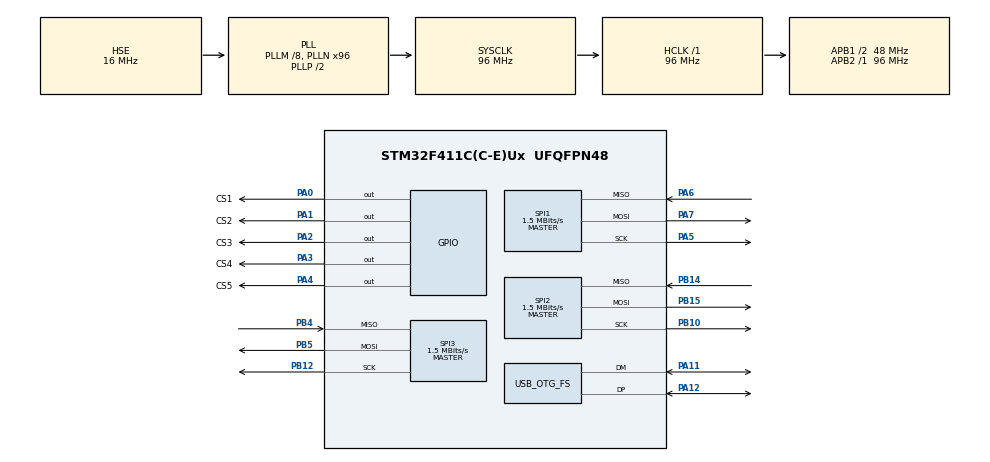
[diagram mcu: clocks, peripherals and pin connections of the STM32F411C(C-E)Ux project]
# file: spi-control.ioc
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Mcu.Family=STM32F4
Mcu.Name=STM32F411C(C-E)Ux
Mcu.Package=UFQFPN48
NVIC.OTG_FS_IRQn=true\:1\:0\:true\:false\:true\:false\:true\:true
NVIC.PriorityGroup=NVIC_PRIORITYGROUP_4
NVIC.TIM1_UP_TIM10_IRQn=true\:0\:0\:true\:false\:true\:true\:true\:true
PA0-WKUP.GPIO_Label=CS1
PA0-WKUP.PinState=GPIO_PIN_SET
PA0-WKUP.Signal=GPIO_Output
PA1.GPIO_Label=CS2
PA1.PinState=GPIO_PIN_SET
PA1.Signal=GPIO_Output
PA11.Mode=Device_Only
PA11.Signal=USB_OTG_FS_DM
PA12.Mode=Device_Only
PA12.Signal=USB_OTG_FS_DP
PA13.Mode=Serial_Wire
PA13.Signal=SYS_JTMS-SWDIO
PA14.Mode=Serial_Wire
PA14.Signal=SYS_JTCK-SWCLK
PA2.GPIO_Label=CS3
PA2.PinState=GPIO_PIN_SET
PA2.Signal=GPIO_Output
PA3.GPIO_Label=CS4
PA3.PinState=GPIO_PIN_SET
PA3.Signal=GPIO_Output
PA4.GPIO_Label=CS5
PA4.PinState=GPIO_PIN_SET
PA4.Signal=GPIO_Output
PA5.Mode=Full_Duplex_Master
PA5.Signal=SPI1_SCK
PA6.Mode=Full_Duplex_Master
PA6.Signal=SPI1_MISO
PA7.Mode=Full_Duplex_Master
PA7.Signal=SPI1_MOSI
PB10.Mode=Full_Duplex_Master
PB10.Signal=SPI2_SCK
PB12.Mode=Full_Duplex_Master
PB12.Signal=SPI3_SCK
PB14.Mode=Full_Duplex_Master
PB14.Signal=SPI2_MISO
PB15.Mode=Full_Duplex_Master
PB15.Signal=SPI2_MOSI
PB4.Mode=Full_Duplex_Master
PB4.Signal=SPI3_MISO
PB5.Mode=Full_Duplex_Master
PB5.Signal=SPI3_MOSI
PH0\ -\ OSC_IN.Mode=HSE-External-Oscillator
PH0\ -\ OSC_IN.Signal=RCC_OSC_IN
PH1\ -\ OSC_OUT.Mode=HSE-External-Oscillator
PH1\ -\ OSC_OUT.Signal=RCC_OSC_OUT
ProjectManager.HeapSize=0x200
ProjectManager.StackSize=0x400
ProjectManager.TargetToolchain=STM32CubeIDE
RCC.48MHZClocksFreq_Value=48000000
RCC.AHBFreq_Value=96000000
RCC.APB1CLKDivider=RCC_HCLK_DIV2
RCC.APB1Freq_Value=48000000
RCC.APB1TimFreq_Value=96000000
RCC.APB2Freq_Value=96000000
RCC.APB2TimFreq_Value=96000000
RCC.CortexFreq_Value=96000000
RCC.HCLKFreq_Value=96000000
RCC.HSE_VALUE=16000000
RCC.HSI_VALUE=16000000
RCC.LSE_VALUE=32768
RCC.PLLM=8
RCC.PLLN=96
RCC.SYSCLKFreq_VALUE=96000000
RCC.SYSCLKSource=RCC_SYSCLKSOURCE_PLLCLK
RCC.VCOOutputFreq_Value=192000000
SPI1.BaudRatePrescaler=SPI_BAUDRATEPRESCALER_64
SPI1.CalculateBaudRate=1.5 MBits/s
SPI1.DataSize=SPI_DATASIZE_8BIT
SPI1.Direction=SPI_DIRECTION_2LINES
SPI1.Mode=SPI_MODE_MASTER
SPI1.VirtualType=VM_MASTER
SPI2.BaudRatePrescaler=SPI_BAUDRATEPRESCALER_32
SPI2.CalculateBaudRate=1.5 MBits/s
SPI2.Direction=SPI_DIRECTION_2LINES
SPI2.Mode=SPI_MODE_MASTER
SPI2.VirtualType=VM_MASTER
SPI3.BaudRatePrescaler=SPI_BAUDRATEPRESCALER_32
SPI3.CalculateBaudRate=1.5 MBits/s
SPI3.Direction=SPI_DIRECTION_2LINES
SPI3.Mode=SPI_MODE_MASTER
SPI3.VirtualType=VM_MASTER
TIM1.Period=5000-1
TIM1.Prescaler=96-1
USB_DEVICE.CLASS_NAME_FS=CDC
USB_DEVICE.PRODUCT_STRING_CDC_FS=soft-hand
USB_DEVICE.VirtualMode=Cdc
USB_DEVICE.VirtualModeFS=Cdc_FS
USB_OTG_FS.VirtualMode=Device_Only
VP_TIM1_VS_ClockSourceINT.Mode=Internal
VP_USB_DEVICE_VS_USB_DEVICE_CDC_FS.Mode=CDC_FS
board=custom

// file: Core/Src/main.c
/* USER CODE BEGIN Header */
/**
  ******************************************************************************
  * @file           : main.c
  * @brief          : Main program body
  ******************************************************************************
  * @attention
  *
  * Copyright (c) 2024 STMicroelectronics.
  * All rights reserved.
  *
  * This software is licensed under terms that can be found in the LICENSE file
  * in the root directory of this software component.
  * If no LICENSE file comes with this software, it is provided AS-IS.
  *
  ******************************************************************************
  */
/* USER CODE END Header */
#include "main.h"
#include "usb_device.h"

/* USER CODE BEGIN Includes */
#include "app.h"
/* USER CODE END Includes */

SPI_HandleTypeDef hspi1;
SPI_HandleTypeDef hspi2;
SPI_HandleTypeDef hspi3;

TIM_HandleTypeDef htim1;

void SystemClock_Config(void);
static void MX_GPIO_Init(void);
static void MX_SPI1_Init(void);
static void MX_SPI2_Init(void);
static void MX_SPI3_Init(void);
static void MX_TIM1_Init(void);

int main(void)
{

  /* MCU Configuration--------------------------------------------------------*/

  /* Reset of all peripherals, Initializes the Flash interface and the Systick. */
  HAL_Init();

  /* Configure the system clock */
  SystemClock_Config();

  /* Initialize all configured peripherals */
  MX_GPIO_Init();
  MX_SPI1_Init();
  MX_SPI2_Init();
  MX_SPI3_Init();
  MX_USB_DEVICE_Init();
  MX_TIM1_Init();

  /* Infinite loop */
  /* USER CODE BEGIN WHILE */
  HAL_Delay(10);
  App_Init();
  while (1)
  {
	  App_Update();
    /* USER CODE END WHILE */

  }
}

void SystemClock_Config(void)
{
  RCC_OscInitTypeDef RCC_OscInitStruct = {0};
  RCC_ClkInitTypeDef RCC_ClkInitStruct = {0};

  /** Configure the main internal regulator output voltage
  */
  __HAL_RCC_PWR_CLK_ENABLE();
  __HAL_PWR_VOLTAGESCALING_CONFIG(PWR_REGULATOR_VOLTAGE_SCALE1);

  /** Initializes the RCC Oscillators according to the specified parameters
  * in the RCC_OscInitTypeDef structure.
  */
  RCC_OscInitStruct.OscillatorType = RCC_OSCILLATORTYPE_HSE;
  RCC_OscInitStruct.HSEState = RCC_HSE_ON;
  RCC_OscInitStruct.PLL.PLLState = RCC_PLL_ON;
  RCC_OscInitStruct.PLL.PLLSource = RCC_PLLSOURCE_HSE;
  RCC_OscInitStruct.PLL.PLLM = 8;
  RCC_OscInitStruct.PLL.PLLN = 96;
  RCC_OscInitStruct.PLL.PLLP = RCC_PLLP_DIV2;
  RCC_OscInitStruct.PLL.PLLQ = 4;
  if (HAL_RCC_OscConfig(&RCC_OscInitStruct) != HAL_OK)
  {
    Error_Handler();
  }

  /** Initializes the CPU, AHB and APB buses clocks
  */
  RCC_ClkInitStruct.ClockType = RCC_CLOCKTYPE_HCLK|RCC_CLOCKTYPE_SYSCLK
                              |RCC_CLOCKTYPE_PCLK1|RCC_CLOCKTYPE_PCLK2;
  RCC_ClkInitStruct.SYSCLKSource = RCC_SYSCLKSOURCE_PLLCLK;
  RCC_ClkInitStruct.AHBCLKDivider = RCC_SYSCLK_DIV1;
  RCC_ClkInitStruct.APB1CLKDivider = RCC_HCLK_DIV2;
  RCC_ClkInitStruct.APB2CLKDivider = RCC_HCLK_DIV1;

  if (HAL_RCC_ClockConfig(&RCC_ClkInitStruct, FLASH_LATENCY_3) != HAL_OK)
  {
    Error_Handler();
  }
}

static void MX_SPI1_Init(void)
{

  /* SPI1 parameter configuration*/
  hspi1.Instance = SPI1;
  hspi1.Init.Mode = SPI_MODE_MASTER;
  hspi1.Init.Direction = SPI_DIRECTION_2LINES;
  hspi1.Init.DataSize = SPI_DATASIZE_8BIT;
  hspi1.Init.CLKPolarity = SPI_POLARITY_LOW;
  hspi1.Init.CLKPhase = SPI_PHASE_1EDGE;
  hspi1.Init.NSS = SPI_NSS_SOFT;
  hspi1.Init.BaudRatePrescaler = SPI_BAUDRATEPRESCALER_64;
  hspi1.Init.FirstBit = SPI_FIRSTBIT_MSB;
  hspi1.Init.TIMode = SPI_TIMODE_DISABLE;
  hspi1.Init.CRCCalculation = SPI_CRCCALCULATION_DISABLE;
  hspi1.Init.CRCPolynomial = 10;
  if (HAL_SPI_Init(&hspi1) != HAL_OK)
  {
    Error_Handler();
  }

}

static void MX_SPI2_Init(void)
{

  /* SPI2 parameter configuration*/
  hspi2.Instance = SPI2;
  hspi2.Init.Mode = SPI_MODE_MASTER;
  hspi2.Init.Direction = SPI_DIRECTION_2LINES;
  hspi2.Init.DataSize = SPI_DATASIZE_8BIT;
  hspi2.Init.CLKPolarity = SPI_POLARITY_LOW;
  hspi2.Init.CLKPhase = SPI_PHASE_1EDGE;
  hspi2.Init.NSS = SPI_NSS_SOFT;
  hspi2.Init.BaudRatePrescaler = SPI_BAUDRATEPRESCALER_32;
  hspi2.Init.FirstBit = SPI_FIRSTBIT_MSB;
  hspi2.Init.TIMode = SPI_TIMODE_DISABLE;
  hspi2.Init.CRCCalculation = SPI_CRCCALCULATION_DISABLE;
  hspi2.Init.CRCPolynomial = 10;
  if (HAL_SPI_Init(&hspi2) != HAL_OK)
  {
    Error_Handler();
  }

}

static void MX_SPI3_Init(void)
{

  /* SPI3 parameter configuration*/
  hspi3.Instance = SPI3;
  hspi3.Init.Mode = SPI_MODE_MASTER;
  hspi3.Init.Direction = SPI_DIRECTION_2LINES;
  hspi3.Init.DataSize = SPI_DATASIZE_8BIT;
  hspi3.Init.CLKPolarity = SPI_POLARITY_LOW;
  hspi3.Init.CLKPhase = SPI_PHASE_1EDGE;
  hspi3.Init.NSS = SPI_NSS_SOFT;
  hspi3.Init.BaudRatePrescaler = SPI_BAUDRATEPRESCALER_32;
  hspi3.Init.FirstBit = SPI_FIRSTBIT_MSB;
  hspi3.Init.TIMode = SPI_TIMODE_DISABLE;
  hspi3.Init.CRCCalculation = SPI_CRCCALCULATION_DISABLE;
  hspi3.Init.CRCPolynomial = 10;
  if (HAL_SPI_Init(&hspi3) != HAL_OK)
  {
    Error_Handler();
  }

}

static void MX_TIM1_Init(void)
{

  TIM_ClockConfigTypeDef sClockSourceConfig = {0};
  TIM_MasterConfigTypeDef sMasterConfig = {0};

  htim1.Instance = TIM1;
  htim1.Init.Prescaler = 96-1;
  htim1.Init.CounterMode = TIM_COUNTERMODE_UP;
  htim1.Init.Period = 5000-1;
  htim1.Init.ClockDivision = TIM_CLOCKDIVISION_DIV1;
  htim1.Init.RepetitionCounter = 0;
  htim1.Init.AutoReloadPreload = TIM_AUTORELOAD_PRELOAD_DISABLE;
  if (HAL_TIM_Base_Init(&htim1) != HAL_OK)
  {
    Error_Handler();
  }
  sClockSourceConfig.ClockSource = TIM_CLOCKSOURCE_INTERNAL;
  if (HAL_TIM_ConfigClockSource(&htim1, &sClockSourceConfig) != HAL_OK)
  {
    Error_Handler();
  }
  sMasterConfig.MasterOutputTrigger = TIM_TRGO_RESET;
  sMasterConfig.MasterSlaveMode = TIM_MASTERSLAVEMODE_DISABLE;
  if (HAL_TIMEx_MasterConfigSynchronization(&htim1, &sMasterConfig) != HAL_OK)
  {
    Error_Handler();
  }

}

static void MX_GPIO_Init(void)
{
  GPIO_InitTypeDef GPIO_InitStruct = {0};

  /* GPIO Ports Clock Enable */
  __HAL_RCC_GPIOH_CLK_ENABLE();
  __HAL_RCC_GPIOA_CLK_ENABLE();
  __HAL_RCC_GPIOB_CLK_ENABLE();

  /*Configure GPIO pin Output Level */
  HAL_GPIO_WritePin(GPIOA, CS1_Pin|CS2_Pin|CS3_Pin|CS4_Pin
                          |CS5_Pin, GPIO_PIN_SET);

  /*Configure GPIO pins : CS1_Pin CS2_Pin CS3_Pin CS4_Pin
                           CS5_Pin */
  GPIO_InitStruct.Pin = CS1_Pin|CS2_Pin|CS3_Pin|CS4_Pin
                          |CS5_Pin;
  GPIO_InitStruct.Mode = GPIO_MODE_OUTPUT_PP;
  GPIO_InitStruct.Pull = GPIO_NOPULL;
  GPIO_InitStruct.Speed = GPIO_SPEED_FREQ_LOW;
  HAL_GPIO_Init(GPIOA, &GPIO_InitStruct);

}

void Error_Handler(void)
{
  __disable_irq();
  while (1)
  {
  }
}
